# MMCSD_0 register map
Vendor: Texas Instruments
Peripheral module from a debugger description file (folder 66AK2G0x_66AK2G1x).
Registers are 32-bit, access per field, reset 0x0 unless marked. A register's access mark holds for its fields unless they carry their own. Offsets are as the file gives them; lines under a group give offsets from that group; [hi:lo] are bit positions; {n}, {i} and the like mark numbered series; 'fields as' and 'values as' point back to an identical list; <NAME> marks a mode.

## MMCSD_0 (part 1 of 2)
0x00 MMCHS_HL_REV ro reset 0x40200303
  [31:0] REVISION — TI internal data. Identifies revision of peripheral.
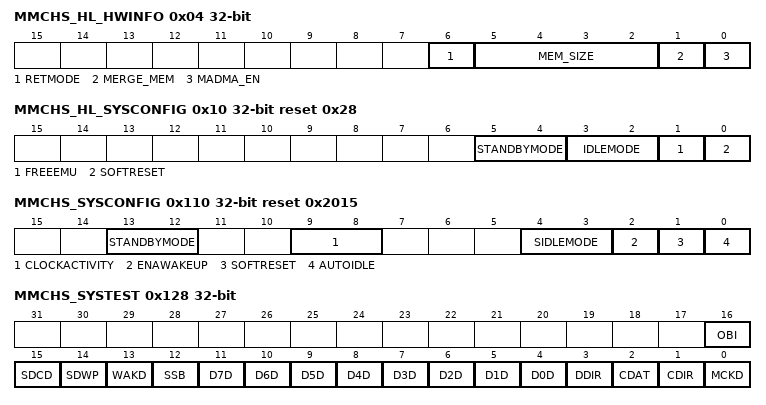
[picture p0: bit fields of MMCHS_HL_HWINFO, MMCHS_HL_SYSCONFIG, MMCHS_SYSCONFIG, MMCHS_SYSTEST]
0x04 MMCHS_HL_HWINFO ro reset not defined
  [6] RETMODE — Retention Mode generic parameter This bit field indicates whether the retention mode is supported using the pin PIRFFRET. 0h (R) = Retention mode disabled. 1h (R) = Retention mode enabled.
  [5:2] MEM_SIZE — Memory size for FIFO buffer 1h (R) = Memory of 512 bytes, max block length is 512 bytes. 2h (R) = Memory of 1024 bytes, max block length is 1024 bytes. 4h (R) = Memory of 2048 bytes, max block length is 2048 bytes. 8h (R) = Memory of 4096 bytes, max block length is 2048 bytes.
  [1] MERGE_MEM — Memory merged for FIFO buffer This bit field defines the configuration of FIFO buffer architecture. If the bit is set STA and DFT shall support clock multiplexing and balancing. 0h (R) = 2 memories instantiated, one per data transfer direction. 1h (R) = A single memory is used with multiplexed addresses, data and clocks.
  [0] MADMA_EN — Master DMA enabled generic parameter This bit defines the configuration of the controller to know if it supports the master DMA management called ADMA. 0h (R) = No Master DMA (ADMA) management supported. 1h (R) = Controller supports ADMA.
0x10 MMCHS_HL_SYSCONFIG reset 0x28
  [5:4] STANDBYMODE rw — Configuration of the local initiator state management mode By definition, initiator may generate read/write transaction as long as it is out of STANDBY state. 0h (R/W) = Force-standby mode: local initiator is unconditionally placed in standby state. Backup mode, for debug only. 1h (R/W) = No-standby mode: local initiator is unconditionally placed out of standby state. Backup mode, for debug only. 2h (R/W) = Smart-standby mode: local initiator standby status depends on local conditions, that is, the module's functional requirement from the initiator. MMC module shall not generate (initiator-related) wakeup events. 3h (R/W) = Smart-Standby wakeup-capable mode: local initiator standby status depends on local conditions, that is, the module's functional requirement from the initiator. MMC module may generate (master-related) wakeup events when in standby state. Mode is only relevant if the appropriate MMC module 'mwakeup' output is implemented.
  [3:2] IDLEMODE rw — Configuration of the local target state management mode By definition, target can handle read/write transaction as long as it is out of IDLE state. 0h (R/W) = Force-idle mode: local target's idle state follows (acknowledges) the system's IDLE requests unconditionally, that is, regardless of the MMC module's internal requirements. Backup mode, for debug only. 1h (R/W) = No-idle mode: local target never enters idle state. Backup mode, for debug only. 2h (R/W) = Smart-idle mode: local target's idle state eventually follows (acknowledges) the system's IDLE requests, depending on the MMC module's internal requirements. MMC module shall not generate (IRQ- or DMA-request-related) wakeup events. 3h (R/W) = Smart-idle wakeup-capable mode: local target's idle state eventually follows (acknowledges) the system's IDLE requests, depending on the MMC module's internal requirements. MMC module may generate (IRQ- or DMA-request-related) wakeup events when in idle state. Mode is only relevant if the appropriate MMC module 'swakeup' output(s) is (are) implemented.
  [1] FREEEMU rw — Sensitivity to emulation (debug) suspend input signal Functionality NOT implemented in MMC. 0h (R/W) = MMC module is sensitive to emulation suspend. 1h (R/W) = MMC module is not sensitive to emulation suspend.
  [0] SOFTRESET rw — Software reset (Optional) 0h (W) = No action. 1h (W) = Initiate software reset . 0h (R) = Reset done, no pending action. 1h (R) = Reset (software or other) ongoing.
0x110 MMCHS_SYSCONFIG reset 0x2015
  [13:12] STANDBYMODE rw — Master interface Power Management, standby/wait control The bit field is only useful when generic parameter 0h (R/W) = Force-standby. Mstandby is forced unconditionnaly. 1h (R/W) = No-standby. Mstandby is never asserted. 2h (R/W) = Smart-standby mode: local initiator standby status depends on local conditions, that is, the module's functional requirement from the initiator. MMC module shall not generate (initiator-related) wakeup events.
  [9:8] CLOCKACTIVITY rw — Clocks activity Bit8: Interface clock. 0h (R/W) = Interface and Functional clock may be switched off. 1h (R/W) = Interface clock is maintained. Functional clock may be switched-off. 2h (R/W) = Functional clock is maintained. Interface clock may be switched-off. 3h (R/W) = Interface and Functional clocks are maintained.
  [4:3] SIDLEMODE rw — Power management 0h (R/W) = If an IDLE request is detected, the MMC acknowledges it unconditionally and goes in Inactive mode. Interrupt and DMA requests are unconditionally de-asserted. 1h (R/W) = If an IDLE request is detected, the request is ignored and the module keeps on behaving normally. 2h (R/W) = Smart-idle mode: local target's idle state eventually follows (acknowledges) the system's IDLE requests, depending on the MMC module's internal requirements. MMC module shall not generate (IRQ- or DMA-request-related) wakeup events. 3h (R/W) = Smart-idle wakeup-capable mode: local target's idle state eventually follows (acknowledges) the system's IDLE requests, depending on the MMC module's internal requirements. MMC module may generate (IRQ- or DMA-request-related) wakeup events when in idle state. Mode is only relevant if the appropriate MMC module 'swakeup' output(s) is (are) implemented.
  [2] ENAWAKEUP rw — Wakeup feature control 0h (R/W) = Wakeup capability is disabled. 1h (R/W) = Wakeup capability is enabled.
  [1] SOFTRESET rw — Software reset The bit is automatically reset by the hardware. During reset, it always returns 0. 0h (W) = No effect. 1h (W) = Trigger a module reset. 0h (R) = Normal mode. 1h (R) = The module is reset.
  [0] AUTOIDLE rw — Internal Clock gating strategy 0h (R/W) = Clocks are free-running. 1h (R/W) = Automatic clock gating strategy is applied, based on the Interconnect and MMC interface activity.
0x114 MMCHS_SYSSTATUS ro
  [0] RESETDONE — Internal Reset Monitoring 0h (R) = Internal module reset is on-going. 1h (R) = Reset completed.
0x124 MMCHS_CSRE rw
  [31:0] CSRE — Card status response error
0x128 MMCHS_SYSTEST
  [16] OBI ro — Out-Of-Band Interrupt (OBI) data value 0h (R) = The Out-of-Band Interrupt pin is driven low. 1h (R) = The Out-of-Band Interrupt pin is driven high.
  [15] SDCD ro — Card detect input signal (MMCi_SDCD) data value 0h (R) = The card detect pin is driven low. 1h (R) = The card detect pin is driven high.
  [14] SDWP ro — Write protect input signal (MMCi_SDWP) data value 0h (R) = The write protect pin MMCi_SDWP is driven low. 1h (R) = The write protect pin MMCi_SDWP is driven high.
  [13] WAKD rw — Wake request output signal data value 0h (W) = The pin SWAKEUP is driven low. 1h (W) = The pin SWAKEUP is driven high. 0h (R) = No action. Returns 0. 1h (R) = No action. Returns 1.
  [12] SSB rw — Set status bit This bit must be cleared prior attempting to clear a status bit of the interrupt status register ( 0h (W) = Clear this SSB bitfield. Writing 0 does not clear already set status bits. 1h (W) = Force to 1 all status bits of the interrupt status register ( 0h (R) = No action. Returns 0. 1h (R) = No action. Returns 1.
  [n+4] D{n}D rw (n=0..7) — DAT{n} input/output signal data value 0h (W) = If SYSTEST[DDIR] = 0 (output mode direction), the DAT{n} line is driven low. 1h (W) = If SYSTEST[DDIR] = 0 (output mode direction), the DAT{n} line is driven high. 0h (R) = If SYSTEST[DDIR] = 1 (input mode direction), returns the value on the DAT{n} line (low). If SYSTEST[DDIR] = 0 (output mode direction), returns 0. 1h (R) = If SYSTEST[DDIR] = 1 (input mode direction), returns the value on the DAT{n} line (high) If SYSTEST[DDIR] = 0 (output mode direction), returns 1.
  [3] DDIR rw — Control of the DAT[7:0] pins direction 0h (W) = The DAT lines are outputs (host to card) 1h (W) = The DAT lines are inputs (card to host) 0h (R) = No action. Returns 0. 1h (R) = No action. Returns 1.
  [2] CDAT rw — CMD input/output signal data value 0h (W) = If SYSTEST[CDIR] = 0 (output mode direction), the CMD line is driven low. 1h (W) = If SYSTEST[CDIR] = 0 (output mode direction), the CMD line is driven high. 0h (R) = If SYSTEST[CDIR] = 1 (input mode direction), returns the value on the CMD line (low). If SYSTEST[CDIR] = 0 (output mode direction), returns 0. 1h (R) = If SYSTEST[CDIR] = 1 (input mode direction), returns the value on the CMD line (high) If SYSTEST[CDIR] = 0 (output mode direction), returns 1.
  [1] CDIR rw — Control of the CMD pin direction 0h (W) = The CMD line is an output (host to card) 1h (W) = The CMD line is an input (card to host) 0h (R) = No action. Returns 0. 1h (R) = No action. Returns 1.
  [0] MCKD rw — MMC clock output signal data value 0h (W) = The output clock is driven low. 1h (W) = The output clock is driven high. 0h (R) = No action. Returns 0. 1h (R) = No action. Returns 1.
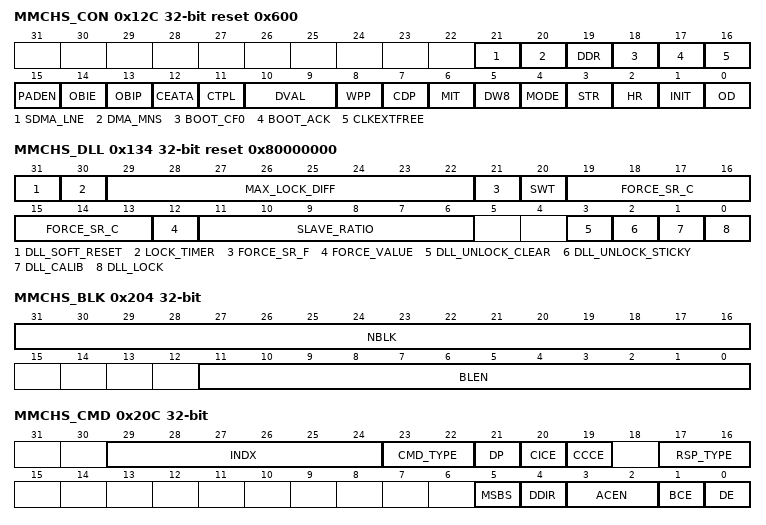
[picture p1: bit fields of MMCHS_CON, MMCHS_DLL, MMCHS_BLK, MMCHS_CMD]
0x12C MMCHS_CON reset 0x600
  [21] SDMA_LNE rw — Slave DMA Level/Edge Request The waveform of the DMA request can be configured either edge sensitive with early de-assertion on first access to 0h (R/W) = Slave DMA edge sensitive, Early DMA de-assertion. 1h (R/W) = Slave DMA level sensitive, Late DMA de-assertion.
  [20] DMA_MNS rw — DMA Master or Slave selection When this bit is set and the controller is configured to use the DMA, Interconnect master interface is used to get datas from system using ADMA2 procedure (direct access to the memory). This option is only available if generic parameter 0h (R/W) = The controller is slave on data transfers with system. 1h (R/W) = The controller is master on data exchange with system, controller must be configured as using DMA.
  [19] DDR rw — Dual Data Rate mode When this bit field is set, the controller uses both clock edge to emit or receive data. Odd bytes are transmitted on falling edges and even bytes are transmitted on rise edges. It only applies on Data bytes and CRC, Start, end bits and CRC status are kept full cycle. 0h (R/W) = Standard mode: data are transmitted on a single edge depending on 1h (R/W) = Data Bytes and CRC are transmitted on both edge.
  [18] BOOT_CF0 rw — Boot status supported This bit field is set when the CMD line need to be forced to '0' for a boot sequence. CMD line is driven to '0' after writing in 0h (W) = CMD line is released when it was previously forced to '0' by a boot sequence. 1h (W) = CMD line forced to '0' is enabled and will be active after writing into 0h (R) = CMD line not forced. 1h (R) = CMD line forced to '0' is enabled.
  [17] BOOT_ACK rw — Boot acknowledge received When this bit is set the controller should receive a boot status on DAT0 line after next command issued. If no status is received a data timeout will be generated. 0h (R/W) = No acknowledge to be received. 1h (R/W) = A boot status will be received on DAT0 line after issuing a command.
  [16] CLKEXTFREE rw — External clock free running This bit field is used to maintain card clock out of transfer transaction to enable slave module for example to generate a synchronous interrupt on DAT[1]. The Clock will be maintain only if 0h (R/W) = External card clock is cut off outside active transaction period. 1h (R/W) = External card clock is maintain even out of active transaction period only if
  [15] PADEN rw — Control Power for MMC Lines This bit field is only useful when MMC PADs contain power saving mechanism to minimize its leakage power. It works as a GPIO that directly control the ACTIVE pin of PADs. Excepted for DAT[1], the signal is also combine outside the module with the dedicated power control 0h (R/W) = ADPIDLE module pin is not forced, it is automatically generated by the MMC fsms. 1h (R/W) = ADPIDLE module pin is forced to active state.
  [14] OBIE rw — Out-of-Band Interrupt Enable MMC cards only: 0h (R/W) = Out-of-Band interrupt detection disabled. 1h (R/W) = Out-of-Band interrupt detection enabled.
  [13] OBIP rw — Out-of-Band Interrupt Polarity MMC cards only: 0h (R/W) = Active high level. 1h (R/W) = Active low level.
  [12] CEATA rw — CE-ATA control mode MMC cards compliant with CE-ATA: By default, this bit is set to 0. It is used to indicate that next commands are considered as specific CE-ATA commands that potentially use 'command completion' features. 0h (R/W) = Standard MMC/SD/SDIO mode. 1h (R/W) = CE-ATA mode next commands are considered as CE-ATA commands.
  [11] CTPL rw — Control Power for DAT[1] line MMC and SD cards: 0h (R/W) = Disable all the input buffers outside of a transaction. 1h (R/W) = Disable all the input buffers except the buffer of DAT[1] outside of a transaction.
  [10:9] DVAL rw — Debounce filter value All cards: 0h (R/W) = 33 us debounce period. 1h (R/W) = 231 us debounce period. 2h (R/W) = 1 ms debounce period. 3h (R/W) = 8,4 ms debounce period.
  [8] WPP rw — Write protect polarity For SD and SDIO cards only: 0h (R/W) = Active high level. 1h (R/W) = Active low level.
  [7] CDP rw — Card detect polarity All cards: 0h (R/W) = Active low level. 1h (R/W) = Active high level.
  [6] MIT rw — MMC interrupt command Only for MMC cards: 0h (R/W) = Command timeout enabled. 1h (R/W) = Command timeout disabled.
  [5] DW8 rw — 8-bit mode MMC select For SD/SDIO cards, this bit must be set to 0. 0h (R/W) = 1-bit or 4-bit Data width (DAT[0] used, MMC, SD cards). 1h (R/W) = 8-bit Data width (DAT[7:0] used, MMC cards).
  [4] MODE rw — Mode select All cards: 0h (R/W) = Functional mode. Transfers to the MMC/SD/SDIO cards follow the card protocol. MMC clock is enabled. MMC/SD transfers are operated under the control of the CMD register. 1h (R/W) = SYSTEST mode The signal pins are configured as general-purpose input/output and the 1024-byte buffer is configured as a stack memory accessible only by the local host or system DMA. The pins retain their default type (input, output or in-out). SYSTEST mode is operated under the control of the SYSTEST register.
  [3] STR rw — Stream command Only for MMC cards: 0h (R/W) = Block oriented data transfer. 1h (R/W) = Stream oriented data transfer.
  [2] HR rw — Broadcast host response Only for MMC cards: 0h (R/W) = The host does not generate a 48-bit response instead of a command. 1h (R/W) = The host generates a 48-bit response instead of a command or a command completion signal disable token.
  [1] INIT rw — Send initialization stream All cards: 0h (R/W) = The host does not send an initialization sequence. 1h (R/W) = The host sends an initialization sequence.
  [0] OD rw — Card open drain mode Only for MMC cards: 0h (R/W) = No Open Drain. 1h (R/W) = Open Drain or Broadcast host response.
0x130 MMCHS_PWCNT
  [15:0] PWRCNT rw — Power counter register This bit field is used to introduce a delay between the PAD ACTIVE pin assertion and the command issued. 0h (R/W) = No additional delay added. 1h (R/W) = TCF delay (card clock period). 2h (R/W) = TCF x 2 delay (card clock period). FFFEh (R/W) = TCF x 65534 delay (card clock period). FFFFh (R/W) = TCF x 65535 delay (card clock period).
0x134 MMCHS_DLL reset 0x80000000
  [31] DLL_SOFT_RESET rw — Soft reset for DLL, active HIGH 0h (W) = No action. 1h (W) = Issue soft reset. 0h (R) = Reset completed. 1h (R) = Reset is in progress.
  [30] LOCK_TIMER rw — Timer for the DLL_LOCK signal to be asserted after reset 0h (R/W) = 1024 cycles (equivalent to DLL fast mode lock). 1h (R/W) = 66560 cycles.
  [29:22] MAX_LOCK_DIFF rw — Maximum number of taps that the master DLL clock period measurement can deviate without resulting in the master DLL losing lock
  [21] FORCE_SR_F rw — Forced fine delay value
  [20] SWT rw — Software Tuning enable The bit shall be set to manage the tuning sequence fully in software.
  [19:13] FORCE_SR_C rw — Forced coarse delay value
  [12] FORCE_VALUE rw — Put forced values to slave DLL, ignoring master DLL output and ratio value 0h (R/W) = Do not put force value. 1h (R/W) = Put force value.
  [11:6] SLAVE_RATIO rw — Fraction of a clock cycle for the shift to be implemented, in units of 256ths of a clock cycle 0h (R/W) = 0 degree delay. 2h (R/W) = 45 degrees delay. 4h (R/W) = 90 degrees delay. 6h (R/W) = 135 degrees delay. 8h (R/W) = 180 degrees delay. Ah (R/W) = 225 degrees delay. Ch (R/W) = 270 degrees delay. Eh (R/W) = 315 degrees delay. 10h (R/W) = Full clock delay. 3Fh (R/W) = 4 clocks delay.
  [3] DLL_UNLOCK_CLEAR rw — Clears the PHY_REG_STATUS_MDLL_UNLOCK_STICKY flags of the DLL 0h (R/W) = No effect. 1h (R/W) = Clears the flag.
  [2] DLL_UNLOCK_STICKY ro — Asserted when any single period measurement exceeds MAX_LOCK_DIFF
  [1] DLL_CALIB rw — Enables Slave DLL to update new delay values 0h (R/W) = Disabled. 1h (R/W) = Enabled.
  [0] DLL_LOCK ro — Master DLL lock status 0h (R) = DLL is not locked. 1h (R) = DLL is locked.
0x200 MMCHS_SDMASA rw
  [31:0] SDMA_ARG2 — SDMA System Address / Argument 2 This register contains the physical system memory address used for DMA transfers or the second argument for the Auto CMD23.
0x204 MMCHS_BLK
  [31:16] NBLK rw — Blocks count for current transfer This bit field is enabled when Block count Enable ( 0h (R/W) = Stop count. 1h (R/W) = 1 block. 2h (R/W) = 2 blocks. FFFFh (R/W) = 65535 blocks.
  [11:0] BLEN rw — Transfer Block Size This bit field specifies the block size for block data transfers. 0h (R/W) = No data transfer. 1h (R/W) = 1 byte block length. 2h (R/W) = 2 bytes block length. 3h (R/W) = 3 bytes block length. 1FFh (R/W) = 511 bytes block length. 200h (R/W) = 512 bytes block length. 7FFh (R/W) = 2047 bytes block length. 800h (R/W) = 2048 bytes block length.
0x208 MMCHS_ARG rw
  [31:0] ARG — Command argument bits [31-0]
0x20C MMCHS_CMD
  [29:24] INDX rw — Command index Binary encoded value from 0 to 63 specifying the command number send to card. 0h (R/W) = CMD0 or ACMD0. 1h (R/W) = CMD1 or ACMD1. 2h (R/W) = CMD2 or ACMD2. 3h (R/W) = CMD3 or ACMD3. 4h (R/W) = CMD4 or ACMD4. 5h (R/W) = CMD5 or ACMD5. 6h (R/W) = CMD6 or ACMD6. 7h (R/W) = CMD7 or ACMD7. 8h (R/W) = CMD8 or ACMD8. 9h (R/W) = CMD9 or ACMD9. Ah (R/W) = CMD10 or ACMD10. Bh (R/W) = CMD11 or ACMD11. Ch (R/W) = CMD12 or ACMD12. Dh (R/W) = CMD13 or ACMD13. Eh (R/W) = CMD14 or ACMD14. Fh (R/W) = CMD15 or ACMD15. 10h (R/W) = CMD16 or ACMD16. 11h (R/W) = CMD17 or ACMD17. 12h (R/W) = CMD18 or ACMD18. 13h (R/W) = CMD19 or ACMD19. 14h (R/W) = CMD20 or ACMD20. 15h (R/W) = CMD21 or ACMD21. 16h (R/W) = CMD22 or ACMD22. 17h (R/W) = CMD23 or ACMD23. 18h (R/W) = CMD24 or ACMD24. 19h (R/W) = CMD25 or ACMD25. 1Ah (R/W) = CMD26 or ACMD26. 1Bh (R/W) = CMD27 or ACMD27. 1Ch (R/W) = CMD28 or ACMD28. 1Dh (R/W) = CMD29 or ACMD29. 1Eh (R/W) = CMD30 or ACMD30. 1Fh (R/W) = CMD31 or ACMD31. 20h (R/W) = CMD32 or ACMD32. 21h (R/W) = CMD33 or ACMD33. 22h (R/W) = CMD34 or ACMD34. 23h (R/W) = CMD35 or ACMD35. 24h (R/W) = CMD36 or ACMD36. 25h (R/W) = CMD37 or ACMD37. 26h (R/W) = CMD38 or ACMD38. 27h (R/W) = CMD39 or ACMD39. 28h (R/W) = CMD40 or ACMD40. 29h (R/W) = CMD41 or ACMD41. 2Ah (R/W) = CMD42 or ACMD42. 2Bh (R/W) = CMD43 or ACMD43. 2Ch (R/W) = CMD44 or ACMD44. 2Dh (R/W) = CMD45 or ACMD45. 2Eh (R/W) = CMD46 or ACMD46. 2Fh (R/W) = CMD47 or ACMD47. 30h (R/W) = CMD48 or ACMD48. 31h (R/W) = CMD49 or ACMD49. 32h (R/W) = CMD50 or ACMD50. 33h (R/W) = CMD51 or ACMD51. 34h (R/W) = CMD52 or ACMD52. 35h (R/W) = CMD53 or ACMD53. 36h (R/W) = CMD54 or ACMD54. 37h (R/W) = CMD55 or ACMD55. 38h (R/W) = CMD56 or ACMD56. 39h (R/W) = CMD57 or ACMD57. 3Ah (R/W) = CMD58 or ACMD58. 3Bh (R/W) = CMD59 or ACMD59. 3Ch (R/W) = CMD60 or ACMD60. 3Dh (R/W) = CMD61 or ACMD61. 3Eh (R/W) = CMD62 or ACMD62. 3Fh (R/W) = CMD63 or ACMD63.
  [23:22] CMD_TYPE rw — Command type This bit field specifies three types of special command: Suspend, Resume and Abort. These bits shall be set to 00b for all other commands. 0h (R/W) = Others Commands. 1h (R/W) = CMD52 for writing 'Bus Suspend' in CCCR. 2h (R/W) = CMD52 for writing 'Function Select' in CCCR. 3h (R/W) = Abort command CMD12, CMD52 for writing ' I/O Abort' in CCCR.
  [21] DP rw — Data present select This bit field indicates that data is present and DAT line shall be used. It must be set to 0 in the following conditions: - command with no data transfer but using busy signal on DAT[0]. - command using only CMD line. - Resume command. 0h (R/W) = Command with no data transfer. 1h (R/W) = Command with data transfer.
  [20] CICE rw — Command Index check enable This bit must be set to 1 to enable index check on command response to compare the index field in the response against the index of the command. If the index is not the same in the response as in the command, it is reported as a command index error ( 0h (R/W) = Index check disable. 1h (R/W) = Index check enable.
  [19] CCCE rw — Command CRC check enable This bit must be set to 1 to enable CRC7 check on command response to protect the response against transmission errors on the bus. If an error is detected, it is reported as a command CRC error ( 0h (R/W) = CRC7 check disable. 1h (R/W) = CRC7 check enable.
  [17:16] RSP_TYPE rw — Response type This bits defines the response type of the command. 0h (R/W) = No response. 1h (R/W) = Response Length 136 bits. 2h (R/W) = Response Length 48 bits. 3h (R/W) = Response Length 48 bits with busy after response.
  [5] MSBS rw — Multi/Single block select This bit must be set to 1 for data transfer in case of multi block command. For any others command this bit shall be set to 0. 0h (R/W) = Single block. If this bit is 0, it is not necessary to set the register 1h (R/W) = Multi block. When Block Count is disabled (
  [4] DDIR rw — Data transfer Direction SelectThis bit defines either data transfer will be a read or a write 0h (R/W) = Data Write (host to card). 1h (R/W) = Data Read (card to host).
  [3:2] ACEN rw — Auto CMD Enable - SD card only This field determines use of auto command functions. There are two methods to stop Multiple-block read and write operation. 1. Auto CMD12 Enable When this field is set to 01b, the Host Controller issues CMD12 automatically when last block transfer is completed. Auto CMD12 error is indicated to the Auto CMD Error Status register ( 2. Auto CMD23 Enable When this bit field is set to 10b, the Host Controller issues a CMD23 automatically before issuing a command specified in the Command Register. The Host Controller Version 3.00 and later shall support this function. The following conditions are required to use the Auto CMD23. – Auto CMD23 Supported (Host Controller Version is 3.00 or later). – A memory card that supports CMD23 (SCR[33]=1). – If DMA is used, it shall be ADMA. – Only when CMD18 or CMD25 is issued. ( Auto CMD23 can be used with or without ADMA. By writing the Command register, the Host Controller issues a CMD23 first and then issues a command specified by the Command Index in Command register. If response errors of CMD23 are detected, the second command is not issued. A CMD23 error is indicated in the Auto CMD Error Status register ( 0h (R/W) = Auto Command Disabled. 1h (R/W) = Auto CMD12 enable or CCS detection enabled. 2h (R/W) = Auto CMD23 Enable. 3h (R/W) = Reserved.
  [1] BCE rw — Block Count Enable Multiple block transfers only. This bit is used to enable the block count register ( When Block Count is disabled ( 0h (R/W) = Block count disabled for infinite transfer. 1h (R/W) = Block count enabled for multiple block transfer with known number of blocks.
  [0] DE rw — DMA EnableThis bit is used to enable DMA mode for host data access 0h (R/W) = DMA mode disable. 1h (R/W) = DMA mode enable.
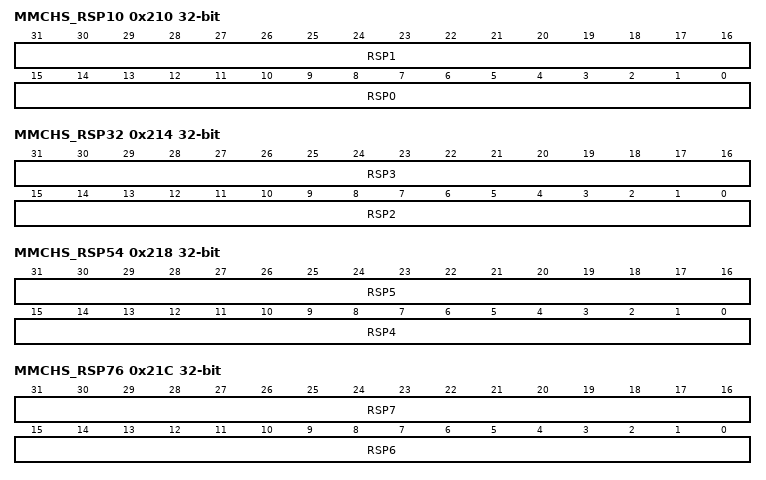
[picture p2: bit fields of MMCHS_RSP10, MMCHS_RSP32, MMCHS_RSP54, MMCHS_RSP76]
0x210 MMCHS_RSP10 ro
  [31:16] RSP1 — Command Response [31:16]
  [15:0] RSP0 — Command Response [15:0]
0x214 MMCHS_RSP32 ro
  [31:16] RSP3 — Command Response [63:48]
  [15:0] RSP2 — Command Response [47:32]
0x218 MMCHS_RSP54 ro
  [31:16] RSP5 — Command Response [95:80]
  [15:0] RSP4 — Command Response [79:64]
0x21C MMCHS_RSP76 ro
  [31:16] RSP7 — Command Response [127:112]
  [15:0] RSP6 — Command Response [111:96]
0x220 MMCHS_DATA rw
  [31:0] DATA — Data Register [31-0] In functional mode (
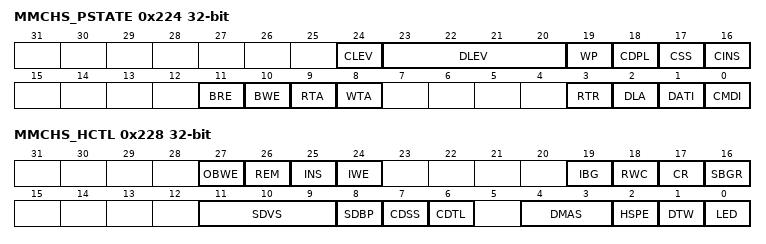
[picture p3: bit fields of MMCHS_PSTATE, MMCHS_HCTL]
0x224 MMCHS_PSTATE ro (reset mask 0xFE03FFFF)
  [24] CLEV — CMD line signal level This status is used to check the CMD line level to recover from errors, and for debugging. 0h (R) = The CMD line level is 0. 1h (R) = The CMD line level is 1.
  [23:20] DLEV — DAT[3:0] line signal level DAT[3] =&gt; bit 23
  [19] WP — Write protect switch pin level For SDIO cards only. 0h (R) = If 1h (R) = If
  [18] CDPL — Card detect pin level This bit reflects the inverse value of the card detect input pin (MMCi_SDCD), debouncing is not performed on this bit and bit is valid only when Card State Stable 0h (R) = The value of the card detect input pin (MMCi_SDCD) is 1. 1h (R) = The value of the card detect input pin (MMCi_SDCD) is 0.
  [17] CSS — Card State Stable This bit is used for testing. It is set to 1 only when Card Detect Pin Level is stable ( 0h (R) = Reset or Debouncing. 1h (R) = No card or card inserted.
  [16] CINS — Card inserted This bit is the debounced value of the card detect input pin (MMCi_SDCD). 0h (R) = If 1h (R) = If
  [11] BRE — Buffer read enable This bit is used for non-DMA read transfers. 0h (R) = Read BLEN bytes disable. 1h (R) = Read BLEN bytes enable. Readable data exists in the buffer.
  [10] BWE — Buffer Write enable This status is used for non-DMA write transfers. 0h (R) = There is no room left in the buffer to write BLEN bytes of data. 1h (R) = There is enough space in the buffer to write BLEN bytes of data.
  [9] RTA — Read transfer active This status is used for detecting completion of a read transfer. It is set to 1 after the end bit of read command or by activating a continue request ( 0h (R) = No valid data on the DAT lines. 1h (R) = read data transfer on going.
  [8] WTA — Write transfer active This status indicates a write transfer active. It is set to 1 after the end bit of write command or by activating a continue request ( 0h (R) = No valid data on the DAT lines. 1h (R) = Write data transfer on going.
  [3] RTR — Re-Tuning Request Host Controller may request Host Driver to execute re-tuning sequence by setting this bit when the data window is shifted by temperature drift and a tuned sampling point does not have a good margin to receive correct data. 0h (R) = Fixed or well tuned sampling clock. 1h (R) = Sampling clock needs re-tuning.
  [2] DLA — DAT line active This status bit indicates whether one of the DAT line is in use. 0h (R) = DAT Line inactive. 1h (R) = DAT Line active.
  [1] DATI — Command inhibit (DAT) This status bit is generated if either DAT line is active ( 0h (R) = Issuing of command using the DAT lines is allowed. 1h (R) = Issuing of command using DAT lines is not allowed.
  [0] CMDI — Command inhibit (CMD) This status bit indicates that the CMD line is in use. 0h (R) = Issuing of command using CMD line is allowed. 1h (R) = Issuing of command using CMD line is not allowed.
0x228 MMCHS_HCTL
  [27] OBWE rw — Wakeup event enable for 'Out-of-Band' Interrupt This bit enables wakeup events for 'Out-of-Band' assertion. 0h (R/W) = Disable wakeup on 'Out-of-Band' Interrupt. 1h (R/W) = Enable wakeup on 'Out-of-Band' Interrupt.
  [26] REM rw — Wakeup event enable on SD card removal This bit enables wakeup events for card removal assertion. Wakeup is generated if the wakeup feature is enabled ( 0h (R/W) = Disable wakeup on card removal. 1h (R/W) = Enable wakeup on card removal.
  [25] INS rw — Wakeup event enable on SD card insertion This bit enables wakeup events for card insertion assertion. Wakeup is generated if the wakeup feature is enabled ( 0h (R/W) = Disable wakeup on card insertion. 1h (R/W) = Enable wakeup on card insertion.
  [24] IWE rw — Wakeup event enable on SD card interrupt This bit enables wakeup events for card interrupt assertion. Wakeup is generated if the wakeup feature is enabled ( 0h (R/W) = Disable wakeup on card interrupt. 1h (R/W) = Enable wakeup on card interrupt.
  [19] IBG rw — Interrupt block at gap This bit is valid only in 4-bit mode of SDIO card to enable interrupt detection in the interrupt cycle at block gap for a multiple block transfer. For MMC cards and for SD card this bit should be set to 0. 0h (R/W) = Disable interrupt detection at the block gap in 4-bit mode. 1h (R/W) = Enable interrupt detection at the block gap in 4-bit mode.
  [18] RWC rw — Read wait control The read wait function is optional only for SDIO cards. If the card supports read wait, this bit must be enabled, then requesting a stop at block gap ( 0h (R/W) = Disable Read Wait Control. Suspend/Resume cannot be supported. 1h (R/W) = Enable Read Wait Control.
  [17] CR rw — Continue request This bit is used to restart a transaction that was stopped by requesting a stop at block gap ( 0h (R/W) = No affect. 1h (R/W) = transfer restart.
  [16] SBGR rw — Stop at block gap request This bit is used to stop executing a transaction at the next block gap. The transfer can restart with a continue request ( 0h (R/W) = Transfer mode. 1h (R/W) = Stop at block gap.
  [11:9] SDVS rw — SD bus voltage select All cards. 5h (R/W) = 1.8 V (Typical). 6h (R/W) = 3.0 V (Typical). 7h (R/W) = 3.3 V (Typical).
  [8] SDBP rw — SD bus power Before setting this bit, the host driver shall select the SD bus voltage ( 0h (R/W) = Power off. 1h (R/W) = Power on.
  [7] CDSS rw — Card Detect Signal Selection This bit selects source for the card detection. When the source for the card detection is switched, the interrupt should be disabled during the switching period by clearing the Interrupt Status/Signal Enable register in order to mask unexpected interrupts caused by the glitch. The Interrupt Status/Signal Enable should be disabled during over the period of debouncing. 0h (R/W) = MMCi_SDCD is selected (for normal use). 1h (R/W) =
  [6] CDTL rw — Card Detect Test Level This bit is enabled while 0h (R/W) = No Card. 1h (R/W) = Card Inserted.
  [4:3] DMAS rw — DMA Select Mode One of supported DMA modes can be selected. The host driver shall check support of DMA modes by referring the Capabilities register 0h (R/W) = Reserved. 1h (R/W) = Reserved. 2h (R/W) = 32-bit Address ADMA2 is selected. 3h (R/W) = Reserved.
  [2] HSPE rw — Before setting this bit, the Host Driver shall check the 0h (R/W) = Тhe Host Controller outputs CMD line and DAT lines at the falling edge of the SD Clock. 1h (R/W) = Тhe Host Controller outputs CMD line and DAT lines at the rising edge of the SD Clock.
  [1] DTW rw — Data transfer width For MMC card, this bit must be set following a valid SWITCH command (CMD6) with the correct value and extend CSD index written in the argument. Prior to this command, the MMC card configuration register (CSD and EXT_CSD) must be verified for compliance with MMC standard specification 4.x (see section 3.6). 0h (R/W) = 1-bit Data width (DAT[0] used). 1h (R/W) = 4-bit Data width (DAT[3:0] used).
  [0] LED ro — Reserved bit LED control feature is not supported.
